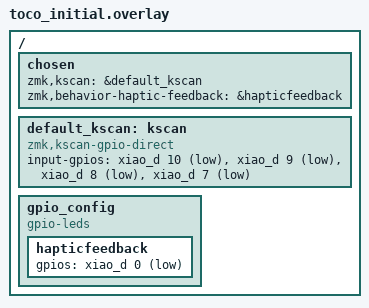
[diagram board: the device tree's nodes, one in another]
/ {
    chosen {
        zmk,kscan = &default_kscan;
    };

    default_kscan: kscan {
        compatible = "zmk,kscan-gpio-direct";

        input-gpios =
            <&xiao_d 10 (GPIO_ACTIVE_LOW | GPIO_PULL_UP)>,
            <&xiao_d 9 (GPIO_ACTIVE_LOW | GPIO_PULL_UP)>,
            <&xiao_d 8 (GPIO_ACTIVE_LOW | GPIO_PULL_UP)>,
            <&xiao_d 7 (GPIO_ACTIVE_LOW | GPIO_PULL_UP)>;
    };

};

/ {
    chosen {
        zmk,behavior-haptic-feedback = &hapticfeedback;
    };

    gpio_config {
        compatible = "gpio-leds";
        hapticfeedback: hapticfeedback {
            gpios = <&xiao_d 0 GPIO_ACTIVE_LOW>;
        };
    };
};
